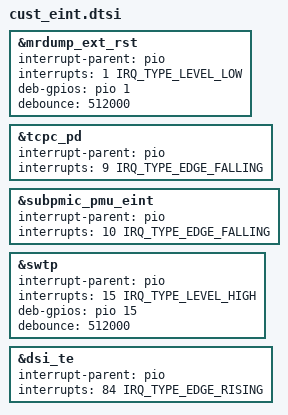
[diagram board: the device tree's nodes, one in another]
/*
 * Generated by MTK SP DrvGen Version: 3.5.160809 for MT6853.
 * 2023-03-11 17:22:13
 * Do Not Modify The File.
 * Copyright Mediatek Inc. (c) 2016.
*/

/*************************
 * EINT DTSI File
*************************/

#include <dt-bindings/interrupt-controller/irq.h>
#include <dt-bindings/interrupt-controller/arm-gic.h>

&mrdump_ext_rst {
	interrupt-parent = <&pio>;
	interrupts = <1 IRQ_TYPE_LEVEL_LOW>;
	deb-gpios = <&pio 1 0>;
	debounce = <512000>;
	status = "okay";
};

&tcpc_pd {
	interrupt-parent = <&pio>;
	interrupts = <9 IRQ_TYPE_EDGE_FALLING>;
	status = "okay";
};

&subpmic_pmu_eint {
	interrupt-parent = <&pio>;
	interrupts = <10 IRQ_TYPE_EDGE_FALLING>;
	status = "okay";
};

&swtp {
	interrupt-parent = <&pio>;
	interrupts = <15 IRQ_TYPE_LEVEL_HIGH>;
	deb-gpios = <&pio 15 0>;
	debounce = <512000>;
	status = "okay";
};

&dsi_te {
	interrupt-parent = <&pio>;
	interrupts = <84 IRQ_TYPE_EDGE_RISING>;
	status = "okay";
};

